# ms_ti_tcp2_rl_config_bus_011 register map
Vendor: Texas Instruments
Peripheral module from a debugger description file (folder TCI6484_C6457).
Registers are 32-bit, access not given, reset 0x0 unless marked. A register's access mark holds for its fields unless they carry their own. Offsets are as the file gives them; lines under a group give offsets from that group; [hi:lo] are bit positions; {n}, {i} and the like mark numbered series; 'fields as' and 'values as' point back to an identical list; <NAME> marks a mode.

## TCP2 — Turbo-decoder Coprocessor (TCP) has designed to meet requirement of high bit rate data decoding as in IS2000 and 3GPP wireless standards.TCP provides very low processing delay because of the highly paralleled architechure. Processing delay can be further reduced by enabling stopping criteria algorithm. TCP reduces board space and power consumption by performing turbo decoding on-chip. TCP is high flexibility to cope with standard evolutions. Accepts any frame length from 40 (3GPP minimum frame size) up to 20730 (IS2000 maximum frame size).
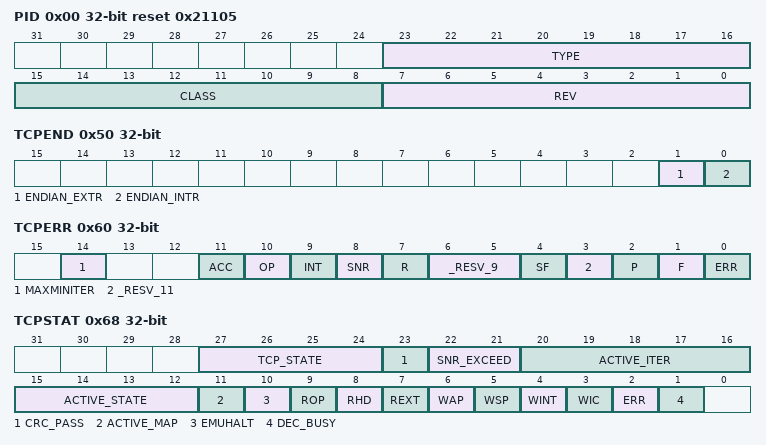
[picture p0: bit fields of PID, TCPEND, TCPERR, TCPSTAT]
0x00 PID reset 0x21105 — PID contains the ID and ID revision of the peripheral.
  [23:16] TYPE ro — Peripheral type
  [15:8] CLASS ro — Identifies the peripheral class
  [7:0] REV ro — Peripheral revision
0x4C TCPEXE — TCPEXE is an execution register
  [2:0] EXECUTION_INSTR wo — Execution instruction
    0=NO (No instruction); 1=START (Start TCP); 4=DEBUG0 (Debug mode; Normal initialization's and wait in MAP state 0); 5=DEBUG6 (Debug mode; execute one MAP decode and wait in MAP state 6); 6=DEBUG (Debug mode; execute remaining MAP decodes and complete normal ending); 7=SOFTRESET (Soft reset all TCP registers except for the execution register, Indian register and other internal registers)
0x50 TCPEND — TCPEND should only be used when the DSP is set to big-endian mode
  [1] ENDIAN_EXTR rw — Endianess view of extrinsic data
    0=32BITS (Packed on 32 bits); 1=NATIVE8 (8 bits native format)
  [0] ENDIAN_INTR rw — Endianess view of interleaver table
    0=32BITS (Packed on 32 bits); 1=NATIVE16 (16 bits native format)
0x60 TCPERR — TCPERR provided error status of TCP
  [14] MAXMINITER ro — Maximum / minimum iteration error
  [11] ACC ro — Spurious TCP memory access
  [10] OP ro — Output parameters load for shared processing
  [9] INT ro — Interleaver table load for shared processing
  [8] SNR ro — SNR Threshold Check
  [7] R ro — Reliability Length
  [6:5] _RESV_9 — (access N)
  [4] SF ro — Sub-frame length
  [3] _RESV_11 — (access N)
  [2] P ro — Prolog length
  [1] F ro — Frame length
  [0] ERR ro — Error Status
0x68 TCPSTAT — TCPSTAT provided status of TCP
  [27:24] TCP_STATE ro — TCP top level state of the state machine
  [23] CRC_PASS ro — CRC Status
    0=FAILED; 1=PASSED
  [22:21] SNR_EXCEED ro — SNR status
    0=MAP01_FAIL (MAP0/1 failed SNR); 1=MAP01_PASS (MAP0/1 passed SNR)
  [20:16] ACTIVE_ITER ro — Active iteration status
  [15:12] ACTIVE_STATE ro — Active MAP decoder state
  [11] ACTIVE_MAP ro — Active MAP status
    0=MAP0 (Processing MAP0); 1=MAP1 (Processing MAP1)
  [10] EMUHALT ro — Defines if the TCP is halt due to emulation
    0=NOT_HALTED (Not halted due to emulation); 1=HALTED (Halted due to emulation)
  [9] ROP ro — Defines if the TCP is waiting for output parameter data to be read
    0=NOT_WAITING; 1=WAITING (Waiting for RAM output registers to be read)
  [8] RHD ro — Defines if the TCP is waiting for hard decision data to be read
    0=NOT_WAITING; 1=WAITING (Waiting for RAM output/decision memory to be read)
  [7] REXT ro — Defines if the TCP is waiting for w0 data to be read
    0=NOT_WAITING; 1=WAITING (Waiting for RAM extrinsic memory 0 to be read)
  [6] WAP ro — Defines if the TCP is waiting for w1 data to be written
    0=NOT_WAITING; 1=WAITING (Waiting for RAM extrinsic memory 1 to be loaded)
  [5] WSP ro — Defines if the TCP is waiting for systematic and parity data to be written
    0=NOT_WAITING; 1=WAITING (Waiting for RAM data/system and parity memory to be loaded)
  [4] WINT ro — Defines if the TCP is waiting for interleaver indexes to be written
    0=NOT_WAITING; 1=WAITING (Waiting for RAM interleaver memory to be loaded)
  [3] WIC ro — Defines if the TCP is waiting for input control words to be written.
    0=NOT_WAITING; 1=WAITING (Waiting for input register to be loaded)
  [2] ERR ro — Defines if the TCP has encountered an error
    0=NO_INPUT_REG (No input register error); 1=INPUT_REG (Input register error)
  [1] DEC_BUSY ro — Decoder status
    0=STATE0 (MAP decoder is in state 0); 1=STATE1_8 (MAP decoder is in state 1 to 8)
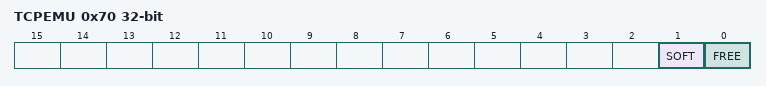
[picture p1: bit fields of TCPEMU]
0x70 TCPEMU — TCPEMU Emulation support helps in system debug.
  [1] SOFT rw — Programmable emulation mode
    0=HALT_EITHER_END (Emulation halt at either end of MAP decode or at end of decode prior to last XEVT. Stop at the end); 1=HALT_XEVT (of MAP decode has priority.)
  [0] FREE rw
    0=SOFT_EMUL (Soft emulation bit takes effect); 1=COMPLETE (TCP2 ignores emulation halt and runs to completion)
